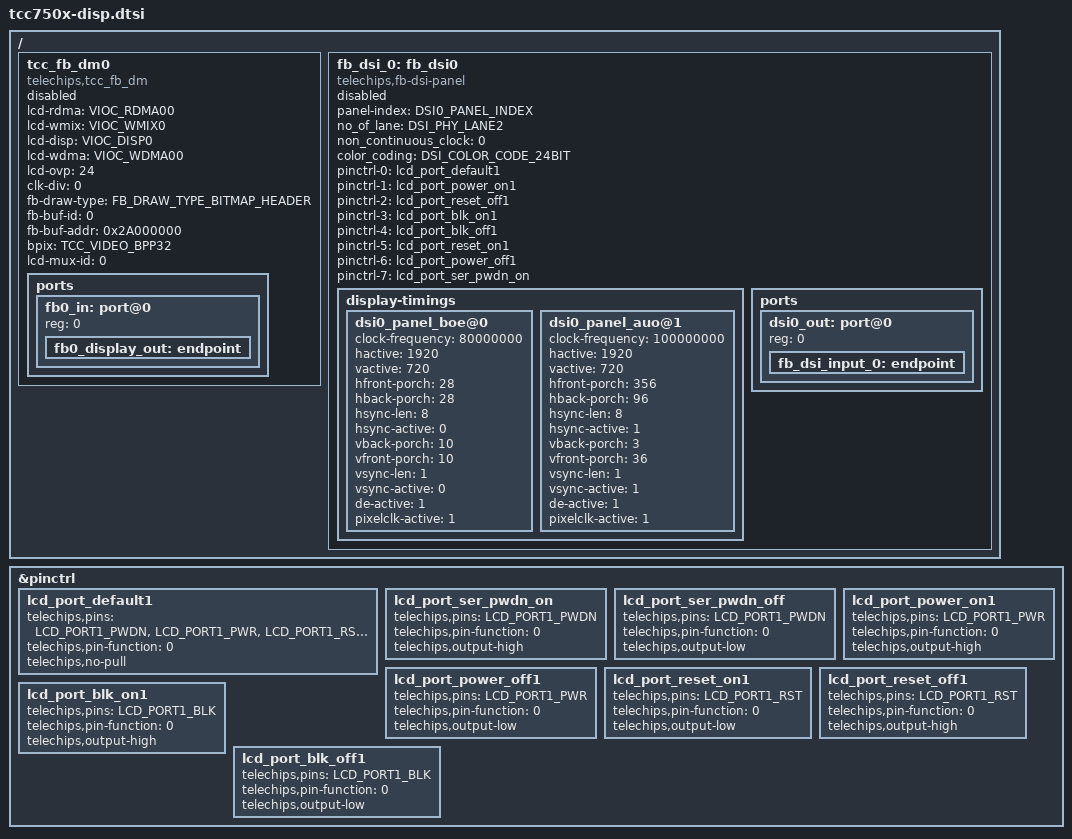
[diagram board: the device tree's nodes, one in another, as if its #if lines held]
// SPDX-License-Identifier: (GPL-2.0-or-later OR MIT)
/*
 * Copyright (C) 2023 Telechips Inc.
 */

#include <dt-bindings/display/telechips-dispdef.h>
#include <dt-bindings/display/tcc750x-vioc.h>
#include <dt-bindings/display/telechips-common-fb_dm_display.h>
#include <dt-bindings/display/tcc750x-fb_dm_display.h>

/ {
	tcc_fb_dm0: tcc_fb_dm0 {
		compatible = "telechips,tcc_fb_dm";
		status = "disabled";

		/* clocks = <&clk_peri PERI_LCD0>; */
		lcd-rdma = <VIOC_RDMA00>;
		lcd-wmix = <VIOC_WMIX0>;
		lcd-disp = <VIOC_DISP0>;
		lcd-wdma = <VIOC_WDMA00>;
		lcd-ovp = <24>;
		clk-div = <0>; /* unused for now */
		fb-draw-type = <FB_DRAW_TYPE_BITMAP_HEADER>;
		fb-buf-id = <0>;
                fb-buf-addr = <0x2A000000>;
		bpix = <TCC_VIDEO_BPP32>;
		lcd-mux-id = <0>;
		ports {
			#address-cells = <1>;
			#size-cells = <0>;
			fb0_in: port@0 {
				#address-cells = <1>;
				#size-cells = <0>;
				reg = <0>;
				fb0_display_out: endpoint {
					//remote-endpoint = <&fb_dsi_input_0>;
				};
			};
		};
	};
	fb_dsi_0:fb_dsi0 {
		compatible = "telechips,fb-dsi-panel";
		status = "disabled";
		panel-index = <DSI0_PANEL_INDEX>;
		no_of_lane = <DSI_PHY_LANE2>; 	// number of lane used
		non_continuous_clock = <0>; 	// continuous clock
		color_coding = <DSI_COLOR_CODE_24BIT>; // <COLOR_CODE_24BIT>

		pinctrl-names = "default", "lcd_on", "reset_off",
				"blk_on", "blk_off", "reset_on",
				"lcd_off", "ser_pwdn_on";
		#if defined(LCD_PORT1_PWDN) && defined(LCD_PORT1_RST) && \
		defined(LCD_PORT1_BLK) && defined(LCD_PORT1_PWR)
		pinctrl-0 = <&lcd_port_default1>;
		pinctrl-1 = <&lcd_port_power_on1>;
		pinctrl-2 = <&lcd_port_reset_off1>;
		pinctrl-3 = <&lcd_port_blk_on1>;
		pinctrl-4 = <&lcd_port_blk_off1>;
		pinctrl-5 = <&lcd_port_reset_on1>;
		pinctrl-6 = <&lcd_port_power_off1>;
		pinctrl-7 = <&lcd_port_ser_pwdn_on>;
		#else
		pinctrl-0 = <>;
		pinctrl-1 = <>;
		pinctrl-2 = <>;
		pinctrl-3 = <>;
		pinctrl-4 = <>;
		pinctrl-5 = <>;
		pinctrl-6 = <>;
		pinctrl-7 = <>;
		#endif
		display-timings {
			dsi0_panel_boe@0 {
				clock-frequency = <80000000>;
				hactive = <1920>;
				vactive = <720>;
				hfront-porch = <28>;
				hback-porch = <28>;
				hsync-len = <8>;
				hsync-active = <0>;
				vback-porch = <10>;
				vfront-porch = <10>;
				vsync-len = <1>;
				vsync-active = <0>;
				de-active = <1>;
				pixelclk-active = <1>;
			};
			dsi0_panel_auo@1 {
				clock-frequency = <100000000>;
				hactive = <1920>;
				vactive = <720>;
				hfront-porch = <356>;
				hback-porch = <96>;
				hsync-len = <8>;
				hsync-active = <1>;
				vback-porch = <3>;
				vfront-porch = <36>;
				vsync-len = <1>;
				vsync-active = <1>;
				de-active = <1>;
				pixelclk-active = <1>;
			};
		};
		ports {
			#address-cells = <1>;
			#size-cells = <0>;
			dsi0_out: port@0 {
				#address-cells = <1>;
				#size-cells = <0>;
				reg = <0>;
				fb_dsi_input_0: endpoint {
					//remote-endpoint = <&fb0_display_out>;
				};
			};
		};
	};
};

&pinctrl {
	/* LCD POWER PORT 1 */
	#if defined(LCD_PORT1_PWDN) && defined(LCD_PORT1_PWR) && \
	    defined(LCD_PORT1_RST) && defined(LCD_PORT1_BLK)
	lcd_port_default1:lcd_port_default1 {
		telechips,pins = LCD_PORT1_PWDN, LCD_PORT1_PWR,
				 LCD_PORT1_RST, LCD_PORT1_BLK;
		telechips,pin-function = <0>;
		telechips,no-pull;
	};
	lcd_port_ser_pwdn_on:lcd_port_ser_pwdn_on {
		telechips,pins = LCD_PORT1_PWDN;
		telechips,pin-function = <0>;
		telechips,output-high;
	};
	lcd_port_ser_pwdn_off:lcd_port_ser_pwdn_off {
		telechips,pins = LCD_PORT1_PWDN;
		telechips,pin-function = <0>;
		telechips,output-low;
	};
	lcd_port_power_on1:lcd_port_power_on1 {
		telechips,pins = LCD_PORT1_PWR;
		telechips,pin-function = <0>;
		telechips,output-high;
	};
	lcd_port_power_off1:lcd_port_power_off1 {
		telechips,pins = LCD_PORT1_PWR;
		telechips,pin-function = <0>;
		telechips,output-low;
	};
	lcd_port_reset_on1:lcd_port_reset_on1 {
		telechips,pins = LCD_PORT1_RST;
		telechips,pin-function = <0>;
		telechips,output-low;
	};
	lcd_port_reset_off1:lcd_port_reset_off1 {
		telechips,pins = LCD_PORT1_RST;
		telechips,pin-function = <0>;
		telechips,output-high;
	};
	lcd_port_blk_on1:lcd_port_blk_on1 {
		telechips,pins = LCD_PORT1_BLK;
		telechips,pin-function = <0>;
		telechips,output-high;
	};
	lcd_port_blk_off1:lcd_port_blk_off1 {
		telechips,pins = LCD_PORT1_BLK;
		telechips,pin-function = <0>;
		telechips,output-low;
	};
	#endif
};
